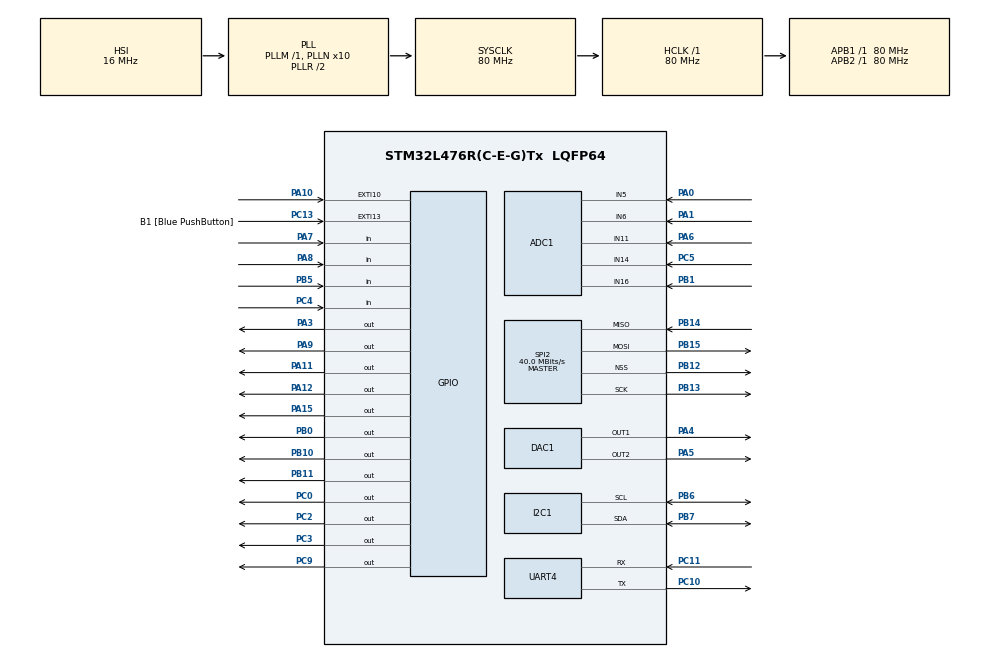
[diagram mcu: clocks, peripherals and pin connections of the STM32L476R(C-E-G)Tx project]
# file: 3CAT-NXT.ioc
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ADC1.Channel-0\#ChannelRegularConversion=ADC_CHANNEL_5
ADC1.NbrOfConversionFlag=1
ADC1.OffsetNumber-0\#ChannelRegularConversion=ADC_OFFSET_NONE
ADC1.Rank-0\#ChannelRegularConversion=1
ADC1.SamplingTime-0\#ChannelRegularConversion=ADC_SAMPLETIME_2CYCLES_5
ADC1.master=1
DAC1.DAC_Channel-DAC_OUT2=DAC_CHANNEL_2
FREERTOS.Tasks01=defaultTask,0,128,StartDefaultTask,Default,NULL,Dynamic,NULL,NULL
FREERTOS.configTIMER_TASK_PRIORITY=5
FREERTOS.configTIMER_TASK_STACK_DEPTH=500
FREERTOS.configTOTAL_HEAP_SIZE=70000
FREERTOS.configUSE_NEWLIB_REENTRANT=1
FREERTOS.configUSE_TIMERS=1
I2C1.Timing=0x10909CEC
Mcu.Family=STM32L4
Mcu.Name=STM32L476R(C-E-G)Tx
Mcu.Package=LQFP64
NVIC.EXTI15_10_IRQn=true\:5\:0\:true\:false\:true\:true\:true\:true
NVIC.PriorityGroup=NVIC_PRIORITYGROUP_4
NVIC.SPI2_IRQn=true\:5\:0\:false\:false\:true\:true\:true\:true
NVIC.TIM1_TRG_COM_TIM17_IRQn=true\:5\:0\:false\:false\:true\:true\:true\:true
NVIC.TIM1_UP_TIM16_IRQn=true\:5\:0\:false\:false\:true\:false\:true\:true
NVIC.TIM2_IRQn=true\:15\:0\:false\:false\:true\:false\:false\:true
NVIC.TIM5_IRQn=true\:15\:0\:true\:false\:true\:true\:true\:true
NVIC.TIM6_DAC_IRQn=true\:5\:0\:false\:false\:true\:true\:true\:true
NVIC.TIM7_IRQn=true\:5\:0\:false\:false\:true\:true\:true\:true
NVIC.TimeBase=TIM2_IRQn
NVIC.TimeBaseIP=TIM2
PA0.Signal=ADCx_IN5
PA1.Signal=ADCx_IN6
PA10.Signal=GPXTI10
PA11.Signal=GPIO_Output
PA12.Signal=GPIO_Output
PA13\ (JTMS-SWDIO).GPIO_Label=TMS
PA13\ (JTMS-SWDIO).Mode=Serial_Wire
PA13\ (JTMS-SWDIO).Signal=SYS_JTMS-SWDIO
PA14\ (JTCK-SWCLK).GPIO_Label=TCK
PA14\ (JTCK-SWCLK).Mode=Serial_Wire
PA14\ (JTCK-SWCLK).Signal=SYS_JTCK-SWCLK
PA15\ (JTDI).Signal=GPIO_Output
PA3.Signal=GPIO_Output
PA4.Signal=COMP_DAC11_group
PA5.Signal=COMP_DAC12_group
PA6.Signal=ADCx_IN11
PA7.Signal=GPIO_Input
PA8.Signal=GPIO_Input
PA9.Signal=GPIO_Output
PB0.Signal=GPIO_Output
PB1.Signal=ADCx_IN16
PB10.Signal=GPIO_Output
PB11.Signal=GPIO_Output
PB12.Mode=NSS_Signal_Hard_Output
PB12.Signal=SPI2_NSS
PB13.Mode=Full_Duplex_Master
PB13.Signal=SPI2_SCK
PB14.Mode=Full_Duplex_Master
PB14.Signal=SPI2_MISO
PB15.Mode=Full_Duplex_Master
PB15.Signal=SPI2_MOSI
PB5.Signal=GPIO_Input
PB6.Mode=I2C
PB6.Signal=I2C1_SCL
PB7.Mode=I2C
PB7.Signal=I2C1_SDA
PC0.Signal=GPIO_Output
PC10.Mode=Asynchronous
PC10.Signal=UART4_TX
PC11.Mode=Asynchronous
PC11.Signal=UART4_RX
PC13.GPIO_Label=B1 [Blue PushButton]
PC13.GPIO_ModeDefaultEXTI=GPIO_MODE_IT_FALLING
PC13.GPIO_PuPd=GPIO_NOPULL
PC13.Signal=GPXTI13
PC14-OSC32_IN\ (PC14).Mode=LSE-External-Oscillator
PC14-OSC32_IN\ (PC14).Signal=RCC_OSC32_IN
PC15-OSC32_OUT\ (PC15).Mode=LSE-External-Oscillator
PC15-OSC32_OUT\ (PC15).Signal=RCC_OSC32_OUT
PC2.Signal=GPIO_Output
PC3.Signal=GPIO_Output
PC4.Signal=GPIO_Input
PC5.Signal=ADCx_IN14
PC9.Signal=GPIO_Output
PH0-OSC_IN\ (PH0).Mode=HSE-External-Oscillator
PH0-OSC_IN\ (PH0).Signal=RCC_OSC_IN
PH1-OSC_OUT\ (PH1).Mode=HSE-External-Oscillator
PH1-OSC_OUT\ (PH1).Signal=RCC_OSC_OUT
ProjectManager.HeapSize=0x200
ProjectManager.StackSize=0x400
ProjectManager.TargetToolchain=STM32CubeIDE
RCC.ADCFreq_Value=64000000
RCC.AHBFreq_Value=80000000
RCC.APB1Freq_Value=80000000
RCC.APB1TimFreq_Value=80000000
RCC.APB2Freq_Value=80000000
RCC.APB2TimFreq_Value=80000000
RCC.CortexFreq_Value=80000000
RCC.FLatency-AdvancedSettings=FLASH_LATENCY_0
RCC.HCLKFreq_Value=80000000
RCC.HSE_VALUE=8000000
RCC.HSI_VALUE=16000000
RCC.MSIClockRange=RCC_MSIRANGE_5
RCC.MSI_VALUE=2000000
RCC.PLLN=10
RCC.PLLSourceVirtual=RCC_PLLSOURCE_HSI
RCC.SYSCLKFreq_VALUE=80000000
RCC.SYSCLKSource=RCC_SYSCLKSOURCE_PLLCLK
RCC.USBFreq_Value=64000000
RCC.VCOOutputFreq_Value=160000000
SH.ADCx_IN11.0=ADC1_IN11,IN11-Single-Ended
SH.ADCx_IN14.0=ADC1_IN14,IN14-Single-Ended
SH.ADCx_IN16.0=ADC1_IN16,IN16-Single-Ended
SH.ADCx_IN5.0=ADC1_IN5,IN5-Single-Ended
SH.ADCx_IN6.0=ADC1_IN6,IN6-Single-Ended
SH.COMP_DAC11_group.0=DAC1_OUT1,DAC_OUT1
SH.COMP_DAC12_group.0=DAC1_OUT2,DAC_OUT2
SPI2.BaudRatePrescaler=SPI_BAUDRATEPRESCALER_2
SPI2.CalculateBaudRate=40.0 MBits/s
SPI2.Direction=SPI_DIRECTION_2LINES
SPI2.Mode=SPI_MODE_MASTER
SPI2.VirtualNSS=VM_NSSHARD
SPI2.VirtualType=VM_MASTER
TIM16.Period=10000 - 1
TIM16.Prescaler=8000 - 1
TIM17.Period=50000-1
TIM17.Prescaler=48000-1
TIM5.AutoReloadPreload=TIM_AUTORELOAD_PRELOAD_ENABLE
TIM5.CounterMode=TIM_COUNTERMODE_DOWN
TIM5.Period=8000-1
TIM7.Period=1000-1
TIM7.Prescaler=20000-1
VP_FREERTOS_VS_CMSIS_V1.Mode=CMSIS_V1
VP_RTC_VS_RTC_Activate.Mode=RTC_Enabled
VP_RTC_VS_RTC_Calendar.Mode=RTC_Calendar
VP_SYS_VS_tim2.Mode=TIM2
VP_TIM16_VS_ClockSourceINT.Mode=Enable_Timer
VP_TIM17_VS_ClockSourceINT.Mode=Enable_Timer
VP_TIM5_VS_ClockSourceINT.Mode=Internal
VP_TIM7_VS_ClockSourceINT.Mode=Enable_Timer
board=NUCLEO-L476RG

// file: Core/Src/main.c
/* USER CODE BEGIN Header */
/**
  ******************************************************************************
  * @file           : main.c
  * @brief          : Main program body
  ******************************************************************************
  * @attention
  *
  * <h2><center>&copy; Copyright (c) 2022 STMicroelectronics.
  * All rights reserved.</center></h2>
  *
  * This software component is licensed by ST under BSD 3-Clause license,
  * the "License"; You may not use this file except in compliance with the
  * License. You may obtain a copy of the License at:
  *                        opensource.org/licenses/BSD-3-Clause
  *
  ******************************************************************************
  */
/* USER CODE END Header */
#include "main.h"
#include "cmsis_os.h"

ADC_HandleTypeDef hadc1;

DAC_HandleTypeDef hdac1;

I2C_HandleTypeDef hi2c1;

RTC_HandleTypeDef hrtc;

SPI_HandleTypeDef hspi2;

TIM_HandleTypeDef htim5;
TIM_HandleTypeDef htim7;
TIM_HandleTypeDef htim16;
TIM_HandleTypeDef htim17;

UART_HandleTypeDef huart4;
/* USER CODE BEGIN PV */
uint8_t timer_counter = 0;		//TEST
uint8_t beacon_counter = 0;		//COMMS BEACON
uint8_t timeout_counter = 0; 	//COMMS TIMEOUT
uint8_t start_timer = false;	//TO SKIP STARTING TIMER IRQ
uint8_t stop_timer = false;		//TO SKIP STOPPING TIMER IRQ

uint8_t photo_vect[]={0xFF, 0xD8, 0xFF, 0xE0, 0x00, 0x10, 0x4A, 0x46, 0x49, 0x46, 0x00, 0x01, 0x01, 0x00, 0x00, 0x01,
	  				0x00, 0x01, 0x00, 0x00, 0xFF, 0xE2, 0x02, 0x28, 0x49, 0x43, 0x43, 0x5F, 0x50, 0x52, 0x4F, 0x46,
	  				0x49, 0x4C, 0x45, 0x00, 0x01, 0x01, 0x00, 0x00, 0x02, 0x18, 0x00, 0x00, 0x00, 0x00, 0x04, 0x30,
	  				0x00, 0x00, 0x6D, 0x6E, 0x74, 0x72, 0x52, 0x47, 0x42, 0x20, 0x58, 0x59, 0x5A, 0x20, 0x00, 0x00,
	  				0x00, 0x00, 0x00, 0x00, 0x00, 0x00, 0x00, 0x00, 0x00, 0x00, 0x61, 0x63, 0x73, 0x70, 0x00, 0x00,
	  				0x00, 0x00, 0x00, 0x00, 0x00, 0x00, 0x00, 0x00, 0x00, 0x00, 0x00, 0x00, 0x00, 0x00, 0x00, 0x00,
	  				0x00, 0x00, 0x00, 0x00, 0x00, 0x00, 0x00, 0x00, 0x00, 0x01, 0x00, 0x00, 0xF6, 0xD6, 0x00, 0x01,
	  				0x00, 0x00, 0x00, 0x00, 0xD3, 0x2D, 0x00, 0x00, 0x00, 0x00, 0x00, 0x00, 0x00, 0x00, 0x00, 0x00,
	  				0x00, 0x00, 0x00, 0x00, 0x00, 0x00, 0x00, 0x00, 0x00, 0x00, 0x00, 0x00, 0x00, 0x00, 0x00, 0x00,
	  				0x00, 0x00, 0x00, 0x00, 0x00, 0x00, 0x00, 0x00, 0x00, 0x00, 0x00, 0x00, 0x00, 0x00, 0x00, 0x00,
	  				0x00, 0x00, 0x00, 0x00, 0x00, 0x00, 0x00, 0x00, 0x00, 0x09, 0x64, 0x65, 0x73, 0x63, 0x00, 0x00,
	  				0x00, 0xF0, 0x00, 0x00, 0x00, 0x74, 0x72, 0x58, 0x59, 0x5A, 0x00, 0x00, 0x01, 0x64, 0x00, 0x00,
	  				0x00, 0x14, 0x67, 0x58, 0x59, 0x5A, 0x00, 0x00, 0x01, 0x78, 0x00, 0x00, 0x00, 0x14, 0x62, 0x58,
	  				0x59, 0x5A, 0x00, 0x00, 0x01, 0x8C, 0x00, 0x00, 0x00, 0x14, 0x72, 0x54, 0x52, 0x43, 0x00, 0x00,
	  				0x01, 0xA0, 0x00, 0x00, 0x00, 0x28, 0x67, 0x54, 0x52, 0x43, 0x00, 0x00, 0x01, 0xA0, 0x00, 0x00,
	  				0x00, 0x28, 0x62, 0x54, 0x52, 0x43, 0x00, 0x00, 0x01, 0xA0, 0x00, 0x00, 0x00, 0x28, 0x77, 0x74,
	  				0x70, 0x74, 0x00, 0x00, 0x01, 0xC8, 0x00, 0x00, 0x00, 0x14, 0x63, 0x70, 0x72, 0x74, 0x00, 0x00,
	  				0x01, 0xDC, 0x00, 0x00, 0x00, 0x3C, 0x6D, 0x6C, 0x75, 0x63, 0x00, 0x00, 0x00, 0x00, 0x00, 0x00,
	  				0x00, 0x01, 0x00, 0x00, 0x00, 0x0C, 0x65, 0x6E, 0x55, 0x53, 0x00, 0x00, 0x00, 0x58, 0x00, 0x00,
	  				0x00, 0x1C, 0x00, 0x73, 0x00, 0x52, 0x00, 0x47, 0x00, 0x42, 0x00, 0x00, 0x00, 0x00, 0x00, 0x00,
	  				0x00, 0x00, 0x00, 0x00, 0x00, 0x00, 0x00, 0x00, 0x00, 0x00, 0x00, 0x00, 0x00, 0x00, 0x00, 0x00,
	  				0x00, 0x00, 0x00, 0x00, 0x00, 0x00, 0x00, 0x00, 0x00, 0x00, 0x00, 0x00, 0x00, 0x00, 0x00, 0x00,
	  				0x00, 0x00, 0x00, 0x00, 0x00, 0x00, 0x00, 0x00, 0x00, 0x00, 0x00, 0x00, 0x00, 0x00, 0x00, 0x00,
	  				0x00, 0x00, 0x00, 0x00, 0x00, 0x00, 0x00, 0x00, 0x00, 0x00, 0x00, 0x00, 0x00, 0x00, 0x00, 0x00,
	  				0x00, 0x00, 0x00, 0x00, 0x00, 0x00, 0x00, 0x00, 0x00, 0x00, 0x58, 0x59, 0x5A, 0x20, 0x00, 0x00,
	  				0x00, 0x00, 0x00, 0x00, 0x6F, 0xA2, 0x00, 0x00, 0x38, 0xF5, 0x00, 0x00, 0x03, 0x90, 0x58, 0x59,
	  				0x5A, 0x20, 0x00, 0x00, 0x00, 0x00, 0x00, 0x00, 0x62, 0x99, 0x00, 0x00, 0xB7, 0x85, 0x00, 0x00,
	  				0x18, 0xDA, 0x58, 0x59, 0x5A, 0x20, 0x00, 0x00, 0x00, 0x00, 0x00, 0x00, 0x24, 0xA0, 0x00, 0x00,
	  				0x0F, 0x84, 0x00, 0x00, 0xB6, 0xCF, 0x70, 0x61, 0x72, 0x61, 0x00, 0x00, 0x00, 0x00, 0x00, 0x04,
	  				0x00, 0x00, 0x00, 0x02, 0x66, 0x66, 0x00, 0x00, 0xF2, 0xA7, 0x00, 0x00, 0x0D, 0x59, 0x00, 0x00,
	  				0x13, 0xD0, 0x00, 0x00, 0x0A, 0x5B, 0x00, 0x00, 0x00, 0x00, 0x00, 0x00, 0x00, 0x00, 0x58, 0x59,
	  				0x5A, 0x20, 0x00, 0x00, 0x00, 0x00, 0x00, 0x00, 0xF6, 0xD6, 0x00, 0x01, 0x00, 0x00, 0x00, 0x00,
	  				0xD3, 0x2D, 0x6D, 0x6C, 0x75, 0x63, 0x00, 0x00, 0x00, 0x00, 0x00, 0x00, 0x00, 0x01, 0x00, 0x00,
	  				0x00, 0x0C, 0x65, 0x6E, 0x55, 0x53, 0x00, 0x00, 0x00, 0x20, 0x00, 0x00, 0x00, 0x1C, 0x00, 0x47,
	  				0x00, 0x6F, 0x00, 0x6F, 0x00, 0x67, 0x00, 0x6C, 0x00, 0x65, 0x00, 0x20, 0x00, 0x49, 0x00, 0x6E,
	  				0x00, 0x63, 0x00, 0x2E, 0x00, 0x20, 0x00, 0x32, 0x00, 0x30, 0x00, 0x31, 0x00, 0x36, 0xFF, 0xDB,
	  				0x00, 0x43, 0x00, 0x03, 0x02, 0x02, 0x02, 0x02, 0x02, 0x03, 0x02, 0x02, 0x02, 0x03, 0x03, 0x03,
	  				0x03, 0x04, 0x06, 0x04, 0x04, 0x04, 0x04, 0x04, 0x08, 0x06, 0x06, 0x05, 0x06, 0x09, 0x08, 0x0A,
	  				0x0A, 0x09, 0x08, 0x09, 0x09, 0x0A, 0x0C, 0x0F, 0x0C, 0x0A, 0x0B, 0x0E, 0x0B, 0x09, 0x09, 0x0D,
	  				0x11, 0x0D, 0x0E, 0x0F, 0x10, 0x10, 0x11, 0x10, 0x0A, 0x0C, 0x12, 0x13, 0x12, 0x10, 0x13, 0x0F,
	  				0x10, 0x10, 0x10, 0xFF, 0xDB, 0x00, 0x43, 0x01, 0x03, 0x03, 0x03, 0x04, 0x03, 0x04, 0x08, 0x04,
	  				0x04, 0x08, 0x10, 0x0B, 0x09, 0x0B, 0x10, 0x10, 0x10, 0x10, 0x10, 0x10, 0x10, 0x10, 0x10, 0x10,
	  				0x10, 0x10, 0x10, 0x10, 0x10, 0x10, 0x10, 0x10, 0x10, 0x10, 0x10, 0x10, 0x10, 0x10, 0x10, 0x10,
	  				0x10, 0x10, 0x10, 0x10, 0x10, 0x10, 0x10, 0x10, 0x10, 0x10, 0x10, 0x10, 0x10, 0x10, 0x10, 0x10,
	  				0x10, 0x10, 0x10, 0x10, 0x10, 0x10, 0x10, 0x10, 0xFF, 0xC0, 0x00, 0x11, 0x08, 0x00, 0x78, 0x00,
	  				0xA0, 0x03, 0x01, 0x22, 0x00, 0x02, 0x11, 0x01, 0x03, 0x11, 0x01, 0xFF, 0xC4, 0x00, 0x1C, 0x00,
	  				0x00, 0x01, 0x05, 0x01, 0x01, 0x01, 0x00, 0x00, 0x00, 0x00, 0x00, 0x00, 0x00, 0x00, 0x00, 0x00,
	  				0x04, 0x00, 0x05, 0x06, 0x07, 0x08, 0x09, 0x01, 0x0A, 0xFF, 0xC4, 0x00, 0x35, 0x10, 0x00, 0x02,
	  				0x01, 0x03, 0x02, 0x04, 0x04, 0x05, 0x03, 0x02, 0x07, 0x01, 0x00, 0x00, 0x00, 0x00, 0x00, 0x04,
	  				0x05, 0x06, 0x07, 0x14, 0x01, 0x24, 0x08, 0x15, 0x34, 0x61, 0x11, 0x16, 0x44, 0x54, 0x02, 0x17,
	  				0x25, 0x31, 0x64, 0x21, 0x35, 0x51, 0x26, 0x41, 0x27, 0x33, 0x36, 0x45, 0x65, 0x81, 0x84, 0xF0,
	  				0xFF, 0xC4, 0x00, 0x19, 0x01, 0x00, 0x03, 0x01, 0x01, 0x01, 0x00, 0x00, 0x00, 0x00, 0x00, 0x00,
	  				0x00, 0x00, 0x00, 0x00, 0x00, 0x00, 0x03, 0x04, 0x05, 0x01, 0x06, 0xFF, 0xC4, 0x00, 0x2A, 0x11,
	  				0x01, 0x00, 0x02, 0x00, 0x05, 0x03, 0x03, 0x02, 0x07, 0x00, 0x00, 0x00, 0x00, 0x00, 0x00, 0x00,
	  				0x00, 0x03, 0x13, 0x01, 0x04, 0x11, 0x41, 0x61, 0x05, 0x14, 0x23, 0x02, 0x12, 0x51, 0x21, 0x31,
	  				0x24, 0x33, 0x52, 0x62, 0x91, 0xA1, 0xE1, 0xFF, 0xDA, 0x00, 0x0C, 0x03, 0x01, 0x00, 0x02, 0x11,
	  				0x03, 0x11, 0x00, 0x3F, 0x00, 0xEA, 0x58, 0x84, 0x20, 0x08, 0xF5, 0x6B, 0x52, 0xA1, 0x48, 0x53,
	  				0xED, 0x4E, 0xB9, 0xF6, 0x4C, 0xE4, 0xAF, 0x10, 0x97, 0x53, 0xCF, 0x95, 0x43, 0x73, 0x8E, 0xBD,
	  				0xB4, 0xF4, 0x66, 0x95, 0xE3, 0x46, 0xFC, 0x66, 0x35, 0xE4, 0x78, 0x57, 0xB6, 0xA7, 0x3F, 0xEA,
	  				0xC7, 0x1E, 0x98, 0x6B, 0xF1, 0x0C, 0xEA, 0xBB, 0xA9, 0xAD, 0xD7, 0x41, 0x36, 0x35, 0x22, 0xB2,
	  				0xCE, 0x73, 0x86, 0x8F, 0x25, 0xB6, 0x71, 0x78, 0x23, 0xB2, 0x89, 0xA2, 0x08, 0xDE, 0xF2, 0x50,
	  				0xD1, 0x48, 0x8A, 0xE1, 0x8D, 0x2D, 0x92, 0xB9, 0x67, 0x08, 0xA3, 0x7B, 0xC1, 0x55, 0x72, 0x05,
	  				0xA8, 0x9E, 0x61, 0x2B, 0xF4, 0xC4, 0x7E, 0x24, 0x95, 0x09, 0x08, 0xAC, 0xB0, 0x22, 0x89, 0xF7,
	  				0x1D, 0x65, 0xBA, 0xB0, 0xB5, 0x13, 0xDA, 0x8A, 0xAB, 0x90, 0x6A, 0xE4, 0xFD, 0xC5, 0xE5, 0xBF,
	  				0xFE, 0xF1, 0x24, 0x02, 0x6C, 0x68, 0x47, 0xF9, 0x3F, 0x71, 0x61, 0x8E, 0xAD, 0x82, 0x0A, 0xAB,
	  				0x90, 0x6A, 0x04, 0x1D, 0x9B, 0x10, 0xD0, 0x10, 0x13, 0x0C, 0x76, 0x0A, 0xC3, 0x00, 0xFA, 0x36,
	  				0x28, 0x8E, 0x29, 0x2F, 0x54, 0x7D, 0xAA, 0xA3, 0x1A, 0xD3, 0x47, 0x7C, 0x1A, 0x6F, 0x4F, 0x0D,
	  				0x3B, 0x68, 0x5A, 0xB5, 0xB5, 0x5C, 0x85, 0x1D, 0x00, 0xCC, 0xDB, 0x9F, 0x6D, 0x3E, 0xC7, 0x28,
	  				0x6F, 0xCD, 0xC8, 0x7A, 0xF0, 0x56, 0x4D, 0xBC, 0xEB, 0xDB, 0x4F, 0x46, 0x12, 0xF9, 0x66, 0xAB,
	  				0xEC, 0xAD, 0x54, 0xD5, 0x95, 0x24, 0xE5, 0x61, 0x28, 0xDB, 0xCE, 0xFA, 0xD2, 0x2A, 0xDA, 0x6F,
	  				0x12, 0xA6, 0xDC, 0x46, 0x1C, 0x8A, 0xB7, 0x52, 0x66, 0x35, 0x82, 0x91, 0x5A, 0x41, 0x4A, 0x27,
	  				0xB5, 0x1A, 0xA5, 0xB6, 0x64, 0x83, 0xFD, 0xAF, 0x7A, 0x42, 0xA5, 0x9C, 0x00, 0x8F, 0xCB, 0x38,
	  				0x08, 0xA2, 0x79, 0x81, 0x7D, 0x61, 0x20, 0x89, 0x87, 0xEC, 0x00, 0x52, 0x90, 0xE1, 0x6A, 0x27,
	  				0x86, 0x3A, 0xE1, 0xE1, 0xAA, 0x35, 0x7A, 0x92, 0x40, 0x6A, 0x6D, 0x3E, 0xE1, 0x41, 0x6D, 0xA7,
	  				0xDC, 0x6A, 0xC3, 0x00, 0x29, 0x44, 0xFB, 0x82, 0xB6, 0x3A, 0x82, 0x00, 0x35, 0x02, 0x0E, 0xCD,
	  				0x82, 0x61, 0x80, 0x34, 0xB9, 0xD5, 0x1E, 0xA8, 0x9F, 0x71, 0xD7, 0x0C, 0x40, 0x02, 0x05, 0xA8,
	  				0x21, 0x12, 0x87, 0x4D, 0x78, 0xC6, 0xBE, 0xFA, 0x4B, 0xCA, 0x79, 0x1A, 0x15, 0xED, 0xA7, 0xAC,
	  				0x31, 0xFB, 0x6E, 0x76, 0x0B, 0x96, 0x98, 0xE7, 0x12, 0x8D, 0xBC, 0xEE, 0xED, 0xB7, 0x48, 0xA5,
	  				0x42, 0xE1, 0x7C, 0x31, 0x55, 0xBA, 0xB4, 0x56, 0xA1, 0x70, 0x12, 0x93, 0x87, 0xCC, 0x6B, 0x38,
	  				0x12, 0x59, 0xCD, 0xD1, 0x2B, 0x89, 0xFA, 0x3C, 0x0F, 0xE5, 0x9A, 0x18, 0x24, 0x09, 0x50, 0xB9,
	  				0x87, 0xB1, 0x21, 0x4D, 0xEF, 0x09, 0x07, 0x96, 0xE7, 0x26, 0x1A, 0xE8, 0x49, 0x04, 0x4D, 0x1F,
	  				0x87, 0xD6, 0x8A, 0xB7, 0x80, 0x8A, 0x53, 0xD4, 0xD9, 0x36, 0x51, 0x34, 0x61, 0xC2, 0x9B, 0x71,
	  				0x14, 0xD5, 0x22, 0xAD, 0xCC, 0x66, 0x34, 0x28, 0x0A, 0x96, 0x70, 0x8F, 0xC4, 0xF5, 0x63, 0xB6,
	  				0x1E, 0xD4, 0x4A, 0x27, 0xBA, 0x00, 0x75, 0x6D, 0x3D, 0xA9, 0x1F, 0x6D, 0x3E, 0xE4, 0xAF, 0x0F,
	  				0x6A, 0x34, 0xCB, 0x26, 0x48, 0x0D, 0x42, 0x10, 0x80, 0x04, 0x05, 0x1D, 0x41, 0x00, 0x05, 0x10,
	  				0x50, 0x29, 0x28, 0x26, 0xC4, 0xA2, 0x7D, 0xC2, 0x84, 0xA0, 0x04, 0xD9, 0x49, 0x8C, 0x36, 0x82,
	  				0xA5, 0xB7, 0x8A, 0x93, 0x69, 0x6E, 0x15, 0xEF, 0x14, 0x3C, 0x5E, 0x74, 0xD5, 0x2A, 0xE2, 0x85,
	  				0x53, 0xBE, 0x87, 0x6B, 0x05, 0xD2, 0xFB, 0xE3, 0xF9, 0x06, 0xAC, 0x3C, 0xC9, 0x42, 0x6B, 0x86,
	  				0xF2, 0x6A, 0xEC, 0x86, 0xAA, 0x79, 0x3F, 0xAA, 0x12, 0x09, 0x69, 0x8C, 0x3D, 0x8A, 0x43, 0x81,
	  				0x66, 0x61, 0x8D, 0x4D, 0xCC, 0x02, 0x36, 0xE7, 0x61, 0xAA, 0x59, 0xC4, 0x7F, 0x80, 0x01, 0x1B,
	  				0x73, 0xB0, 0xA2, 0x46, 0xA6, 0xDC, 0xCC, 0x25, 0x54, 0x9C, 0x3B, 0xD3, 0x0D, 0x28, 0x8A, 0x48,
	  				0xE5, 0xB6, 0xE8, 0x03, 0xB4, 0x4C, 0x3B, 0xD3, 0x0D, 0x28, 0x8C, 0x2A, 0x39, 0x6D, 0xBA, 0x69,
	  				0xFA, 0x7B, 0x83, 0xF8, 0x3A, 0x3E, 0xDC, 0xB7, 0x5C, 0x5C, 0xE7, 0xB1, 0x1B, 0xC3, 0x2E, 0x1E,
	  				0x1E, 0xEC, 0x9D, 0x2B, 0x64, 0xE9, 0x7F, 0x35, 0x56, 0x88, 0xE5, 0xD4, 0x0E, 0xFA, 0x42, 0xCA,
	  				0xAB, 0x39, 0x1C, 0xC4, 0x0F, 0x3C, 0xB8, 0x3B, 0x45, 0x3D, 0xA1, 0x9F, 0x34, 0xB6, 0xEC, 0x1C,
	  				0xBF, 0x6F, 0x05, 0x3C, 0xBC, 0x2E, 0x90, 0x8F, 0xB6, 0x5C, 0x17, 0xBA, 0xA4, 0xB7, 0x33, 0x15,
	  				0x47, 0xF8, 0x7C, 0x8E, 0x22, 0x85, 0x54, 0xD8, 0x5B, 0xC0, 0x47, 0xC4, 0x16, 0xD8, 0x20, 0x5B,
	  				0xC0, 0x21, 0x08, 0x42, 0x80, 0x46, 0xC1, 0x4F, 0x1C, 0xEA, 0x8F, 0x40, 0xDB, 0x78, 0x3A, 0x89,
	  				0x40, 0x40, 0xB5, 0x04, 0x5D, 0xC1, 0x4E, 0xFA, 0x4B, 0x28, 0x8C, 0xBA, 0xB8, 0x4F, 0x25, 0x95,
	  				0xA7, 0x72, 0x9D, 0xBA, 0xFC, 0x21, 0xD9, 0xDB, 0xAB, 0x07, 0xAA, 0x0F, 0xC2, 0x68, 0x93, 0x5A,
	  				0xFD, 0x9A, 0x57, 0xF4, 0xD4, 0xB0, 0xA7, 0xEB, 0xA8, 0x3A, 0x65, 0x46, 0x9D, 0x9A, 0x7D, 0x45,
	  				0x3C, 0x3F, 0x9D, 0x4C, 0xD5, 0x78, 0xB8, 0xFB, 0xA5, 0x69, 0xA5, 0x5A, 0x46, 0x8A, 0x4B, 0x2D,
	  				0xAF, 0x75, 0xFD, 0x87, 0x43, 0x9D, 0x8A, 0x63, 0xAA, 0xCC, 0x7C, 0xB1, 0xAD, 0xF8, 0xB1, 0x1F,
	  				0x22, 0x2B, 0x1E, 0x46, 0x94, 0xE7, 0x36, 0x2A, 0xA6, 0xD3, 0xC3, 0x68, 0x2E, 0xE6, 0xDE, 0x09,
	  				0xCA, 0xC2, 0x79, 0xB9, 0xC9, 0xAE, 0xAD, 0xD2, 0x12, 0xDD, 0x78, 0xF7, 0xAD, 0x2B, 0xC9, 0xB9,
	  				0x34, 0x55, 0x6E, 0x76, 0x6D, 0xCE, 0xC0, 0x8D, 0xA7, 0xDC, 0x2D, 0x4D, 0xE2, 0xB9, 0xC9, 0x02,
	  				0x61, 0xE6, 0x74, 0x45, 0x65, 0x14, 0x4D, 0x36, 0xF4, 0xC4, 0xA2, 0x88, 0xC2, 0xEE, 0xDB, 0x74,
	  				0xE8, 0x07, 0x0C, 0xBC, 0x3D, 0xC1, 0xDB, 0x78, 0x15, 0x2B, 0x8A, 0xD3, 0xFD, 0x41, 0xE8, 0xD4,
	  				0x22, 0xBC, 0x2D, 0x59, 0xF8, 0x3B, 0x56, 0xAA, 0x97, 0x1A, 0xE0, 0xA3, 0x97, 0x2A, 0xEF, 0x46,
	  				0xA1, 0xAA, 0xAA, 0xC9, 0x8A, 0x56, 0x1E, 0x2F, 0xE6, 0x35, 0x68, 0x8E, 0x22, 0x89, 0x6F, 0x53,
	  				0x50, 0xCF, 0x9A, 0x5B, 0x76, 0x36, 0xAE, 0x42, 0x37, 0x31, 0x07, 0x47, 0xC5, 0xB7, 0x75, 0x2E,
	  				0x0B, 0xC9, 0xEC, 0xBA, 0x35, 0x0C, 0x15, 0xC4, 0x27, 0x10, 0x93, 0x97, 0x52, 0x7B, 0x65, 0x98,
	  				0xA4, 0x52, 0x43, 0x55, 0xEE, 0xBF, 0x13, 0x97, 0x52, 0x79, 0xB7, 0xB7, 0x8A, 0x44, 0xFA, 0x35,
	  				0x07, 0x5B, 0x0D, 0x67, 0xE9, 0x5B, 0xA8, 0xAB, 0x79, 0xAF, 0x7D, 0x57, 0xDA, 0x0A, 0x76, 0xAE,
	  				0x54, 0xFA, 0x86, 0x80, 0xB7, 0xBC, 0x3D, 0xBD, 0x58, 0x5A, 0xF9, 0x59, 0xC7, 0x51, 0xC4, 0xFC,
	  				0xB0, 0xB5, 0x38, 0x33, 0x9C, 0x4E, 0xA8, 0xDE, 0xBD, 0x89, 0x4F, 0xA5, 0xEA, 0xCB, 0x56, 0xA1,
	  				0xE2, 0x72, 0xDC, 0xD3, 0x76, 0xE5, 0xBB, 0x3A, 0x96, 0xEF, 0x09, 0x3C, 0x2C, 0xB2, 0x79, 0x65,
	  				0xB7, 0x6D, 0x0D, 0xF6, 0xC9, 0xFA, 0x58, 0x7D, 0x4A, 0x6F, 0x9C, 0x4F, 0x60, 0xA4, 0x2A, 0xB2,
	  				0x83, 0x9C, 0xA6, 0xFA, 0xD2, 0xC0, 0xB6, 0x49, 0xE6, 0x4A, 0x67, 0x16, 0x5C, 0xB4, 0x3F, 0x38,
	  				0xEB, 0x4B, 0x21, 0x8E, 0xDD, 0xF4, 0x64, 0xCD, 0x9B, 0xAB, 0x66, 0x54, 0x04, 0x2F, 0x6A, 0xB2,
	  				0xCF, 0xE6, 0x6F, 0xA1, 0x4A, 0x7E, 0x5A, 0x1D, 0xE8, 0x76, 0xB0, 0x5D, 0x16, 0x6C, 0x32, 0xDD,
	  				0xB6, 0x88, 0xF8, 0x9B, 0x0A, 0x6C, 0x14, 0x84, 0xE2, 0x0A, 0x50, 0x14, 0x28, 0x03, 0x4B, 0x5C,
	  				0x2B, 0xC1, 0x55, 0x57, 0x8D, 0x6F, 0x5E, 0x29, 0xF6, 0xD3, 0x79, 0xC2, 0x54, 0xA4, 0x3B, 0xCE,
	  				0x16, 0x05, 0x27, 0x41, 0xE6, 0x35, 0xBD, 0x15, 0xDC, 0x47, 0xF2, 0xDC, 0x86, 0x1B, 0xB7, 0xD1,
	  				0x5F, 0xD3, 0xD6, 0x7F, 0x9C, 0x2B, 0xD0, 0x95, 0xAD, 0xE3, 0xA3, 0xD1, 0xA6, 0xDA, 0x37, 0xAC,
	  				0x4D, 0x1E, 0x8A, 0x71, 0x7D, 0x09, 0x8F, 0xF8, 0xB0, 0x4F, 0x0E, 0x79, 0x44, 0x45, 0x41, 0x9D,
	  				0x92, 0x5C, 0xDF, 0xC1, 0xB9, 0xCC, 0x9C, 0x7D, 0xA2, 0x94, 0xA4, 0xE6, 0x30, 0xDA, 0xC1, 0x2C,
	  				0x0A, 0x7A, 0x61, 0x18, 0x79, 0xE8, 0x99, 0xCE, 0xAD, 0x44, 0x9C, 0x2B, 0x5C, 0x31, 0xD6, 0x26,
	  				0x63, 0x0F, 0x62, 0xE9, 0xE9, 0xEA, 0xE5, 0xE7, 0x9D, 0x35, 0xA4, 0xEB, 0x04, 0x5C, 0x81, 0x52,
	  				0xEA, 0x54, 0xFF, 0x00, 0xB5, 0x24, 0x9E, 0xCD, 0x43, 0x2F, 0xF1, 0x09, 0xC4, 0xE4, 0xE5, 0xD4,
	  				0x94, 0x6D, 0x14, 0x9E, 0xFE, 0x9F, 0xF6, 0x85, 0x3F, 0xF3, 0x22, 0xAA, 0xF2, 0xBF, 0x95, 0x79,
	  				0xE7, 0xD2, 0xBD, 0xA1, 0x20, 0xB4, 0xF6, 0xAE, 0x72, 0xE4, 0x35, 0xFF, 0x00, 0x14, 0x97, 0x58,
	  				0xD9, 0x01, 0xD2, 0xC9, 0x6E, 0xC8, 0xAE, 0x61, 0xAA, 0xAD, 0x3D, 0x37, 0xF2, 0x4E, 0x83, 0xF9,
	  				0xA9, 0x9D, 0xF5, 0x5F, 0x68, 0x0B, 0x6F, 0x6C, 0x9D, 0x2B, 0x0F, 0x3C, 0xDD, 0x71, 0x53, 0xA3,
	  				0xFD, 0x3F, 0x0C, 0x55, 0x37, 0xE6, 0xF0, 0x79, 0xF2, 0x7B, 0x06, 0x98, 0xCC, 0x4E, 0x9F, 0x4B,
	  				0xA3, 0x03, 0x61, 0xF1, 0x2F, 0x68, 0x9E, 0x39, 0x39, 0xC5, 0x2F, 0x2B, 0x07, 0x5A, 0x41, 0xF5,
	  				0xBE, 0xD0, 0xCF, 0xF1, 0x34, 0xDB, 0xD5, 0x23, 0x5B, 0x24, 0x46, 0x9B, 0x7B, 0x41, 0xBD, 0x52,
	  				0x4A, 0x7E, 0x21, 0xAD, 0xA8, 0x8A, 0x6D, 0x14, 0xF1, 0x11, 0x49, 0x12, 0x29, 0xBC, 0x3C, 0xB9,
	  				0x17, 0x96, 0x5A, 0xBE, 0xC8, 0xA5, 0x27, 0x6D, 0xFC, 0xB7, 0x03, 0xF9, 0x64, 0x52, 0xA1, 0xAF,
	  				0x11, 0xA6, 0xDA, 0xC1, 0x2F, 0x6A, 0xDE, 0x9B, 0x9C, 0x4E, 0x2D, 0xBC, 0x23, 0x2F, 0xCB, 0x51,
	  				0xF3, 0x8E, 0x35, 0x9D, 0x83, 0xBB, 0x1D, 0x0C, 0xD6, 0xEC, 0xEF, 0x6B, 0xDA, 0xEF, 0xA8, 0xA8,
	  				0x9B, 0x90, 0xF4, 0xC4, 0xA6, 0x0E, 0x0E, 0xD0, 0xB2, 0xE5, 0xAD, 0x5A, 0x35, 0x24, 0x5E, 0xF5,
	  				0x12, 0xB4, 0xB6, 0x54, 0x7B, 0xCE, 0x55, 0x0A, 0x1A, 0xAD, 0xB4, 0xF9, 0x3C, 0x59, 0x65, 0xBC,
	  				0x25, 0xEC, 0xE4, 0x62, 0xAA, 0xDE, 0xD5, 0xBD, 0x4D, 0xB5, 0xEE, 0xD5, 0x2B, 0xFE, 0x4F, 0xDC,
	  				0xD9, 0x52, 0xD0, 0xFC, 0xE1, 0xA6, 0xF3, 0x4A, 0xAA, 0xAC, 0xB6, 0xF9, 0x8D, 0x67, 0x42, 0xA2,
	  				0xE6, 0x21, 0x98, 0xA9, 0x9F, 0xF0, 0xF7, 0x40, 0x8D, 0x96, 0x04, 0xB5, 0x37, 0x86, 0x35, 0x29,
	  				0x47, 0xBD, 0x30, 0xD6, 0x0A, 0x48, 0x82, 0x46, 0x8B, 0xA7, 0xA8, 0xF2, 0xE0, 0xA4, 0xE8, 0xFC,
	  				0x35, 0x47, 0x5A, 0x22, 0x8F, 0xCC, 0x54, 0xB5, 0x62, 0x69, 0xBC, 0x35, 0x8C, 0x49, 0xA5, 0xAB,
	  				0x6D, 0x5E, 0xE3, 0x28, 0x8A, 0xA9, 0x4D, 0xED, 0x7A, 0x13, 0x1A, 0x71, 0x61, 0x0F, 0x99, 0x54,
	  				0x1D, 0x00, 0x96, 0x4F, 0xD0, 0xC2, 0xF5, 0x66, 0x5F, 0xE2, 0x96, 0xDB, 0xF2, 0x75, 0x54, 0x79,
	  				0xDE, 0xAD, 0xD2, 0xBE, 0x9B, 0x15, 0xB2, 0xDB, 0xA9, 0x3D, 0x4A, 0x78, 0xE2, 0x86, 0xAD, 0x75,
	  				0x62, 0xA5, 0x28, 0xF1, 0x4B, 0x51, 0xC8, 0x96, 0xAF, 0x27, 0xEE, 0x09, 0xC9, 0xFB, 0x9E, 0xA1,
	  				0xE3, 0x71, 0x53, 0xEA, 0x26, 0xF2, 0x6D, 0x1D, 0x00, 0xB0, 0xC9, 0xC1, 0xD6, 0x14, 0x6C, 0x55,
	  				0x2B, 0x45, 0xED, 0x3D, 0xE1, 0x95, 0x5B, 0xA3, 0xF3, 0x02, 0xA9, 0x3A, 0xC2, 0xB8, 0xB5, 0x6D,
	  				0x67, 0x42, 0x84, 0xDE, 0x51, 0x0E, 0x15, 0x35, 0x05, 0xD8, 0xB9, 0x0F, 0x51, 0xED, 0x4A, 0xDB,
	  				0x94, 0xA0, 0xF2, 0xD4, 0xC3, 0x33, 0x55, 0x27, 0x61, 0xEA, 0xAA, 0x92, 0x53, 0xF1, 0x04, 0xDD,
	  				0xD4, 0x9C, 0xAC, 0x25, 0x33, 0xA6, 0x9E, 0xDD, 0x97, 0x05, 0xBD, 0xAF, 0x3D, 0x0B, 0xAF, 0x0A,
	  				0x86, 0x2A, 0xB7, 0x73, 0x38, 0x95, 0xD3, 0xD6, 0xAF, 0xCB, 0x71, 0x78, 0x29, 0x22, 0x58, 0x14,
	  				0x45, 0x36, 0xF7, 0x34, 0x50, 0x51, 0x35, 0x21, 0x65, 0x5B, 0xD7, 0x11, 0x73, 0xAD, 0x39, 0x9C,
	  				0x8B, 0x7D, 0x47, 0x4E, 0xF1, 0x2B, 0x5B, 0xC7, 0x5E, 0x79, 0x3D, 0xA5, 0x20, 0xF0, 0x7A, 0xD2,
	  				0x28, 0xA4, 0x3A, 0x3C, 0xAF, 0x65, 0xBB, 0x69, 0xD2, 0xE0, 0xAD, 0xED, 0x5B, 0xD3, 0x0D, 0x67,
	  				0x60, 0xE5, 0x82, 0xD2, 0x7C, 0x3D, 0xBD, 0x30, 0xAE, 0x77, 0x48, 0x2B, 0x05, 0x8C, 0xD3, 0x12,
	  				0x9B, 0xD4, 0x1D, 0x51, 0x9C, 0xE9, 0x6A, 0xB6, 0xE7, 0x38, 0xDF, 0x17, 0xB2, 0x9C, 0x3D, 0xD2,
	  				0xA9, 0xEF, 0xA6, 0xB7, 0x6D, 0x84, 0xD3, 0xF6, 0x59, 0x04, 0xDB, 0xE7, 0x55, 0x2E, 0xBA, 0x2B,
	  				0x16, 0x9E, 0x9E, 0x3A, 0x28, 0x46, 0x6D, 0xF1, 0xFC, 0xAA, 0xBA, 0x22, 0xCF, 0xCE, 0x57, 0x8D,
	  				0x67, 0x60, 0xE2, 0x45, 0x17, 0x4D, 0xD8, 0xD2, 0x97, 0xB7, 0x16, 0xED, 0x95, 0x11, 0x86, 0x53,
	  				0x46, 0x5C, 0xD3, 0x09, 0x3F, 0x87, 0xC3, 0xEE, 0x79, 0xF0, 0xDD, 0x4F, 0x8A, 0x5E, 0x4B, 0x4A,
	  				0x5E, 0xDA, 0xC2, 0x68, 0xDA, 0xDE, 0x1F, 0xAB, 0x7A, 0x7D, 0xB4, 0x1D, 0x94, 0xB3, 0xE8, 0xCB,
	  				0xB7, 0xA4, 0xD5, 0x66, 0xE7, 0x36, 0x6B, 0xC3, 0xFE, 0x87, 0x61, 0x17, 0xBF, 0xF2, 0xB1, 0xD5,
	  				0x2D, 0x9C, 0x31, 0x0A, 0x9C, 0x3D, 0xD7, 0x15, 0xE7, 0xEC, 0xB0, 0x7F, 0xFA, 0xCB, 0x55, 0x3E,
	  				0x10, 0x34, 0xB7, 0x10, 0x39, 0xDA, 0x6B, 0xA3, 0x8D, 0xE8, 0x6C, 0x94, 0xD2, 0x4D, 0x25, 0x30,
	  				0x93, 0x4B, 0x45, 0x56, 0xED, 0xA7, 0x80, 0x5B, 0x7F, 0xE4, 0x1C, 0xCD, 0xE4, 0x3C, 0x56, 0x7B,
	  				0xBF, 0xAF, 0xF5, 0x5C, 0x32, 0xD5, 0xB3, 0x1B, 0x5B, 0xD7, 0x11, 0xE5, 0x79, 0xCE, 0x96, 0x54,
	  				0x4C, 0xBA, 0x13, 0x0D, 0xA9, 0x09, 0x9B, 0x89, 0xAB, 0x82, 0x11, 0x89, 0x83, 0x7F, 0x35, 0x99,
	  				0x93, 0x2B, 0x87, 0x8B, 0x1D, 0x16, 0xA4, 0x35, 0x25, 0x1F, 0x15, 0xA7, 0x8F, 0xC1, 0xAF, 0x8B,
	  				0x3F, 0xC9, 0x98, 0x78, 0x9A, 0xB6, 0xF5, 0xC5, 0x79, 0x53, 0xEC, 0x91, 0xDA, 0x26, 0x21, 0x1B,
	  				0x19, 0x4C, 0x34, 0xC7, 0x47, 0x9C, 0x87, 0xF1, 0x58, 0xE3, 0x6F, 0xD5, 0x9F, 0xDB, 0xB2, 0x75,
	  				0xC2, 0x6A, 0xFE, 0xC6, 0xE1, 0x14, 0x6E, 0x83, 0xAA, 0x93, 0x6B, 0xF6, 0x37, 0x04, 0x23, 0x55,
	  				0x18, 0x5F, 0x2D, 0xCE, 0x27, 0xD6, 0xA2, 0x2C, 0x3C, 0xCE, 0xB5, 0x11, 0x08, 0x1C, 0x45, 0x25,
	  				0xAD, 0xBF, 0xAE, 0x48, 0x69, 0x89, 0xE7, 0x90, 0xE2, 0x11, 0xDC, 0x02, 0xD6, 0xA2, 0x2E, 0x47,
	  				0x27, 0x69, 0x4C, 0xDE, 0x94, 0xD1, 0x74, 0x9D, 0x79, 0x07, 0x52, 0x7A, 0xE1, 0x08, 0x8B, 0x38,
	  				0xD7, 0xE9, 0x0B, 0x2F, 0xCF, 0x9E, 0x4F, 0xC4, 0xDF, 0x65, 0x96, 0x4A, 0x8F, 0x56, 0xCE, 0x46,
	  				0xE5, 0xA5, 0x0B, 0xA2, 0x9F, 0x17, 0xDF, 0xC1, 0xBD, 0x7F, 0x51, 0x08, 0x93, 0xD2, 0x46, 0x6E,
	  				0x7F, 0xDB, 0x87, 0xF0, 0x76, 0x57, 0x5D, 0x68, 0xF8, 0xC6, 0xA6, 0xEA, 0x79, 0xBF, 0x1D, 0x3F,
	  				0x93, 0x3F, 0xCA, 0xD7, 0x75, 0xC5, 0xEB, 0x9D, 0xE4, 0x70, 0xA9, 0x62, 0x45, 0x7B, 0x5D, 0x7F,
	  				0xB8, 0x84, 0x58, 0x83, 0x06, 0x88, 0xB7, 0xD4, 0x3C, 0x7D, 0x1D, 0x17, 0xA2, 0x29, 0xEB, 0xA6,
	  				0x4F, 0xC5, 0xE1, 0x95, 0xAF, 0x8F, 0xDF, 0x52, 0x5C, 0x21, 0x15, 0xE5, 0x15, 0x3C, 0xF0, 0xF0,
	  				0x18, 0x2A, 0x19, 0x8C, 0x35, 0x44, 0x23, 0x2F, 0xAB, 0xE6, 0x24, 0xF4, 0xFD, 0x30, 0xC4, 0x3F,
	  				0xFF, 0xD9};

uint8_t config_vect[]={0x0A, 0x0A, 0x0A, 0xE0, 0x00, 0x10, 0x4A, 0x46, 0x49, 0x46, 0x00, 0x01, 0x01, 0x00, 0x00, 0x01,
	  				0x00, 0x01, 0x00, 0x00, 0xFF, 0xE2, 0x02, 0x28, 0x49, 0x43, 0x43, 0x5F, 0x50, 0x52};

uint8_t telemetry_vect[]={0x01, 0x01, 0x01, 0x02, 0x02, 0x10, 0x4A, 0x46, 0x49, 0x46, 0x00, 0x01, 0x01, 0x00, 0x00, 0x01,
			0x00, 0x01, 0x00, 0x00, 0xFF, 0xE2, 0x02, 0x28, 0x49, 0x43, 0x43, 0x5F, 0x50, 0x52};

TaskHandle_t FLASH_Handle;
TaskHandle_t OBC_Handle;
TaskHandle_t COMMS_Handle;
TaskHandle_t EPS_Handle;
TaskHandle_t PAYLOAD_Handle;
TaskHandle_t ADCS_Handle;
TaskHandle_t sTIM_Handle;

QueueHandle_t FLASH_Queue;

EventGroupHandle_t xEventGroup;

SemaphoreHandle_t xMutex;

/* USER CODE END PV */

void SystemClock_Config(void);
static void MX_GPIO_Init(void);
static void MX_I2C1_Init(void);
static void MX_RTC_Init(void);
static void MX_SPI2_Init(void);
static void MX_UART4_Init(void);
static void MX_TIM16_Init(void);
static void MX_ADC1_Init(void);
static void MX_DAC1_Init(void);
static void MX_TIM17_Init(void);
static void MX_TIM7_Init(void);
static void MX_TIM5_Init(void);

/* USER CODE BEGIN PFP */
void SystemClockConfig( void );
void Start_timer_16(void);
void Stop_timer_16(void);
void OBC_Task(void const * argument);
void COMMS_Task(void const * argument);
void ADCS_Task(void const * argument);
void PAYLOAD_Task(void const * argument);
void FLASH_Task(void const * argument);
void EPS_Task(void const * argument);
void sTIM_Task(void const * argument);
void Test_Task(void const * argument);

/* USER CODE END PFP */

int main(void)
{

  /* MCU Configuration--------------------------------------------------------*/

  /* Reset of all peripherals, Initializes the Flash interface and the Systick. */
  HAL_Init();

  /* Configure the system clock */
  SystemClock_Config();

  /* Initialize all configured peripherals */
  MX_GPIO_Init();
  MX_I2C1_Init();
  MX_RTC_Init();
  MX_SPI2_Init();
  MX_UART4_Init();
  MX_TIM16_Init();
  MX_ADC1_Init();
  MX_DAC1_Init();
  MX_TIM17_Init();
  MX_TIM7_Init();
  MX_TIM5_Init();
  /* USER CODE BEGIN 2 */
  xTaskCreate( FLASH_Task,     "FLASH",   FLASH_STACK_SIZE, NULL,   FLASH_PRIORITY, &FLASH_Handle  );
    //xTaskCreate( EPS_Task,         "EPS",     EPS_STACK_SIZE, NULL,   EPS_PRIORITY, &EPS_Handle  );
    //xTaskCreate( PAYLOAD_Task, "PAYLOAD", PAYLOAD_STACK_SIZE, NULL, PAYLOAD_PRIORITY, &PAYLOAD_Handle);
    //xTaskCreate( ADCS_Task,       "ADCS",    ADCS_STACK_SIZE, NULL,    ADCS_PRIORITY, &ADCS_Handle   );
    //xTaskCreate( OBC_Task,         "OBC",     OBC_STACK_SIZE, NULL,     OBC_PRIORITY, &OBC_Handle    );
    xTaskCreate( COMMS_Task,     "COMMS",   COMMS_STACK_SIZE, NULL,   COMMS_PRIORITY, &COMMS_Handle  );
    //xTaskCreate( sTIM_Task,     "sTIM",   sTIM_STACK_SIZE, NULL,   sTIM_PRIORITY, &sTIM_Handle  );
    //xTaskCreate( Test_Task,     "Test",   1000, NULL,   1, &Test_Handle  );

  FLASH_Queue = xQueueCreate(10,sizeof(QueueData_t)); // QUEUE : FIFO buffer for controlling the writing on the memory flash

  xEventGroup = xEventGroupCreate();                  // EVENT GROUP : communication object used for blocking events

  xMutex = xSemaphoreCreateMutex();

  vTaskStartScheduler();

  /* USER CODE END 2 */
}

void SystemClock_Config(void)
{
  RCC_OscInitTypeDef RCC_OscInitStruct = {0};
  RCC_ClkInitTypeDef RCC_ClkInitStruct = {0};

  /** Configure the main internal regulator output voltage
  */
  if (HAL_PWREx_ControlVoltageScaling(PWR_REGULATOR_VOLTAGE_SCALE1) != HAL_OK)
  {
    Error_Handler();
  }
  /** Initializes the RCC Oscillators according to the specified parameters
  * in the RCC_OscInitTypeDef structure.
  */
  RCC_OscInitStruct.OscillatorType = RCC_OSCILLATORTYPE_HSI|RCC_OSCILLATORTYPE_LSI;
  RCC_OscInitStruct.HSIState = RCC_HSI_ON;
  RCC_OscInitStruct.HSICalibrationValue = RCC_HSICALIBRATION_DEFAULT;
  RCC_OscInitStruct.LSIState = RCC_LSI_ON;
  RCC_OscInitStruct.PLL.PLLState = RCC_PLL_ON;
  RCC_OscInitStruct.PLL.PLLSource = RCC_PLLSOURCE_HSI;
  RCC_OscInitStruct.PLL.PLLM = 1;
  RCC_OscInitStruct.PLL.PLLN = 10;
  RCC_OscInitStruct.PLL.PLLP = RCC_PLLP_DIV7;
  RCC_OscInitStruct.PLL.PLLQ = RCC_PLLQ_DIV2;
  RCC_OscInitStruct.PLL.PLLR = RCC_PLLR_DIV2;
  if (HAL_RCC_OscConfig(&RCC_OscInitStruct) != HAL_OK)
  {
    Error_Handler();
  }
  /** Initializes the CPU, AHB and APB buses clocks
  */
  RCC_ClkInitStruct.ClockType = RCC_CLOCKTYPE_HCLK|RCC_CLOCKTYPE_SYSCLK
                              |RCC_CLOCKTYPE_PCLK1|RCC_CLOCKTYPE_PCLK2;
  RCC_ClkInitStruct.SYSCLKSource = RCC_SYSCLKSOURCE_PLLCLK;
  RCC_ClkInitStruct.AHBCLKDivider = RCC_SYSCLK_DIV1;
  RCC_ClkInitStruct.APB1CLKDivider = RCC_HCLK_DIV1;
  RCC_ClkInitStruct.APB2CLKDivider = RCC_HCLK_DIV1;

  if (HAL_RCC_ClockConfig(&RCC_ClkInitStruct, FLASH_LATENCY_4) != HAL_OK)
  {
    Error_Handler();
  }
}

static void MX_ADC1_Init(void)
{

  ADC_MultiModeTypeDef multimode = {0};
  ADC_ChannelConfTypeDef sConfig = {0};

  /** Common config
  */
  hadc1.Instance = ADC1;
  hadc1.Init.ClockPrescaler = ADC_CLOCK_ASYNC_DIV1;
  hadc1.Init.Resolution = ADC_RESOLUTION_12B;
  hadc1.Init.DataAlign = ADC_DATAALIGN_RIGHT;
  hadc1.Init.ScanConvMode = ADC_SCAN_DISABLE;
  hadc1.Init.EOCSelection = ADC_EOC_SINGLE_CONV;
  hadc1.Init.LowPowerAutoWait = DISABLE;
  hadc1.Init.ContinuousConvMode = DISABLE;
  hadc1.Init.NbrOfConversion = 1;
  hadc1.Init.DiscontinuousConvMode = DISABLE;
  hadc1.Init.ExternalTrigConv = ADC_SOFTWARE_START;
  hadc1.Init.ExternalTrigConvEdge = ADC_EXTERNALTRIGCONVEDGE_NONE;
  hadc1.Init.DMAContinuousRequests = DISABLE;
  hadc1.Init.Overrun = ADC_OVR_DATA_PRESERVED;
  hadc1.Init.OversamplingMode = DISABLE;
  if (HAL_ADC_Init(&hadc1) != HAL_OK)
  {
    Error_Handler();
  }
  /** Configure the ADC multi-mode
  */
  multimode.Mode = ADC_MODE_INDEPENDENT;
  if (HAL_ADCEx_MultiModeConfigChannel(&hadc1, &multimode) != HAL_OK)
  {
    Error_Handler();
  }
  /** Configure Regular Channel
  */
  sConfig.Channel = ADC_CHANNEL_5;
  sConfig.Rank = ADC_REGULAR_RANK_1;
  sConfig.SamplingTime = ADC_SAMPLETIME_2CYCLES_5;
  sConfig.SingleDiff = ADC_SINGLE_ENDED;
  sConfig.OffsetNumber = ADC_OFFSET_NONE;
  sConfig.Offset = 0;
  if (HAL_ADC_ConfigChannel(&hadc1, &sConfig) != HAL_OK)
  {
    Error_Handler();
  }

}

static void MX_DAC1_Init(void)
{

  DAC_ChannelConfTypeDef sConfig = {0};

  /** DAC Initialization
  */
  hdac1.Instance = DAC1;
  if (HAL_DAC_Init(&hdac1) != HAL_OK)
  {
    Error_Handler();
  }
  /** DAC channel OUT1 config
  */
  sConfig.DAC_SampleAndHold = DAC_SAMPLEANDHOLD_DISABLE;
  sConfig.DAC_Trigger = DAC_TRIGGER_NONE;
  sConfig.DAC_OutputBuffer = DAC_OUTPUTBUFFER_ENABLE;
  sConfig.DAC_ConnectOnChipPeripheral = DAC_CHIPCONNECT_DISABLE;
  sConfig.DAC_UserTrimming = DAC_TRIMMING_FACTORY;
  if (HAL_DAC_ConfigChannel(&hdac1, &sConfig, DAC_CHANNEL_1) != HAL_OK)
  {
    Error_Handler();
  }
  /** DAC channel OUT2 config
  */
  if (HAL_DAC_ConfigChannel(&hdac1, &sConfig, DAC_CHANNEL_2) != HAL_OK)
  {
    Error_Handler();
  }

}

static void MX_I2C1_Init(void)
{

  hi2c1.Instance = I2C1;
  hi2c1.Init.Timing = 0x10909CEC;
  hi2c1.Init.OwnAddress1 = 0;
  hi2c1.Init.AddressingMode = I2C_ADDRESSINGMODE_7BIT;
  hi2c1.Init.DualAddressMode = I2C_DUALADDRESS_DISABLE;
  hi2c1.Init.OwnAddress2 = 0;
  hi2c1.Init.OwnAddress2Masks = I2C_OA2_NOMASK;
  hi2c1.Init.GeneralCallMode = I2C_GENERALCALL_DISABLE;
  hi2c1.Init.NoStretchMode = I2C_NOSTRETCH_DISABLE;
  if (HAL_I2C_Init(&hi2c1) != HAL_OK)
  {
    Error_Handler();
  }
  /** Configure Analogue filter
  */
  if (HAL_I2CEx_ConfigAnalogFilter(&hi2c1, I2C_ANALOGFILTER_ENABLE) != HAL_OK)
  {
    Error_Handler();
  }
  /** Configure Digital filter
  */
  if (HAL_I2CEx_ConfigDigitalFilter(&hi2c1, 0) != HAL_OK)
  {
    Error_Handler();
  }

}

static void MX_RTC_Init(void)
{

  RTC_TimeTypeDef sTime = {0};
  RTC_DateTypeDef sDate = {0};

  /** Initialize RTC Only
  */
  hrtc.Instance = RTC;
  hrtc.Init.HourFormat = RTC_HOURFORMAT_24;
  hrtc.Init.AsynchPrediv = 127;
  hrtc.Init.SynchPrediv = 255;
  hrtc.Init.OutPut = RTC_OUTPUT_DISABLE;
  hrtc.Init.OutPutRemap = RTC_OUTPUT_REMAP_NONE;
  hrtc.Init.OutPutPolarity = RTC_OUTPUT_POLARITY_HIGH;
  hrtc.Init.OutPutType = RTC_OUTPUT_TYPE_OPENDRAIN;
  if (HAL_RTC_Init(&hrtc) != HAL_OK)
  {
    Error_Handler();
  }

  /** Initialize RTC and set the Time and Date
  */
  sTime.Hours = 0x0;
  sTime.Minutes = 0x0;
  sTime.Seconds = 0x0;
  sTime.DayLightSaving = RTC_DAYLIGHTSAVING_NONE;
  sTime.StoreOperation = RTC_STOREOPERATION_RESET;
  if (HAL_RTC_SetTime(&hrtc, &sTime, RTC_FORMAT_BCD) != HAL_OK)
  {
    Error_Handler();
  }
  sDate.WeekDay = RTC_WEEKDAY_MONDAY;
  sDate.Month = RTC_MONTH_JANUARY;
  sDate.Date = 0x1;
  sDate.Year = 0x0;

  if (HAL_RTC_SetDate(&hrtc, &sDate, RTC_FORMAT_BCD) != HAL_OK)
  {
    Error_Handler();
  }

}

static void MX_SPI2_Init(void)
{

  /* SPI2 parameter configuration*/
  hspi2.Instance = SPI2;
  hspi2.Init.Mode = SPI_MODE_MASTER;
  hspi2.Init.Direction = SPI_DIRECTION_2LINES;
  hspi2.Init.DataSize = SPI_DATASIZE_4BIT;
  hspi2.Init.CLKPolarity = SPI_POLARITY_LOW;
  hspi2.Init.CLKPhase = SPI_PHASE_1EDGE;
  hspi2.Init.NSS = SPI_NSS_HARD_OUTPUT;
  hspi2.Init.BaudRatePrescaler = SPI_BAUDRATEPRESCALER_2;
  hspi2.Init.FirstBit = SPI_FIRSTBIT_MSB;
  hspi2.Init.TIMode = SPI_TIMODE_DISABLE;
  hspi2.Init.CRCCalculation = SPI_CRCCALCULATION_DISABLE;
  hspi2.Init.CRCPolynomial = 7;
  hspi2.Init.CRCLength = SPI_CRC_LENGTH_DATASIZE;
  hspi2.Init.NSSPMode = SPI_NSS_PULSE_ENABLE;
  if (HAL_SPI_Init(&hspi2) != HAL_OK)
  {
    Error_Handler();
  }

}

static void MX_TIM5_Init(void)
{

  TIM_ClockConfigTypeDef sClockSourceConfig = {0};
  TIM_MasterConfigTypeDef sMasterConfig = {0};

  htim5.Instance = TIM5;
  htim5.Init.Prescaler = 0;
  htim5.Init.CounterMode = TIM_COUNTERMODE_DOWN;
  htim5.Init.Period = 8000-1;
  htim5.Init.ClockDivision = TIM_CLOCKDIVISION_DIV1;
  htim5.Init.AutoReloadPreload = TIM_AUTORELOAD_PRELOAD_ENABLE;
  if (HAL_TIM_Base_Init(&htim5) != HAL_OK)
  {
    Error_Handler();
  }
  sClockSourceConfig.ClockSource = TIM_CLOCKSOURCE_INTERNAL;
  if (HAL_TIM_ConfigClockSource(&htim5, &sClockSourceConfig) != HAL_OK)
  {
    Error_Handler();
  }
  sMasterConfig.MasterOutputTrigger = TIM_TRGO_RESET;
  sMasterConfig.MasterSlaveMode = TIM_MASTERSLAVEMODE_DISABLE;
  if (HAL_TIMEx_MasterConfigSynchronization(&htim5, &sMasterConfig) != HAL_OK)
  {
    Error_Handler();
  }

}

static void MX_TIM7_Init(void)
{

  TIM_MasterConfigTypeDef sMasterConfig = {0};

  htim7.Instance = TIM7;
  htim7.Init.Prescaler = 20000-1;
  htim7.Init.CounterMode = TIM_COUNTERMODE_UP;
  htim7.Init.Period = 1000-1;
  htim7.Init.AutoReloadPreload = TIM_AUTORELOAD_PRELOAD_DISABLE;
  if (HAL_TIM_Base_Init(&htim7) != HAL_OK)
  {
    Error_Handler();
  }
  sMasterConfig.MasterOutputTrigger = TIM_TRGO_RESET;
  sMasterConfig.MasterSlaveMode = TIM_MASTERSLAVEMODE_DISABLE;
  if (HAL_TIMEx_MasterConfigSynchronization(&htim7, &sMasterConfig) != HAL_OK)
  {
    Error_Handler();
  }

}

static void MX_TIM16_Init(void)
{

  htim16.Instance = TIM16;
  htim16.Init.Prescaler = 8000 - 1;
  htim16.Init.CounterMode = TIM_COUNTERMODE_UP;
  htim16.Init.Period = 10000 - 1;
  htim16.Init.ClockDivision = TIM_CLOCKDIVISION_DIV1;
  htim16.Init.RepetitionCounter = 0;
  htim16.Init.AutoReloadPreload = TIM_AUTORELOAD_PRELOAD_DISABLE;
  if (HAL_TIM_Base_Init(&htim16) != HAL_OK)
  {
    Error_Handler();
  }

}

static void MX_TIM17_Init(void)
{

  htim17.Instance = TIM17;
  htim17.Init.Prescaler = 48000-1;
  htim17.Init.CounterMode = TIM_COUNTERMODE_UP;
  htim17.Init.Period = 50000-1;
  htim17.Init.ClockDivision = TIM_CLOCKDIVISION_DIV1;
  htim17.Init.RepetitionCounter = 0;
  htim17.Init.AutoReloadPreload = TIM_AUTORELOAD_PRELOAD_DISABLE;
  if (HAL_TIM_Base_Init(&htim17) != HAL_OK)
  {
    Error_Handler();
  }

}

static void MX_UART4_Init(void)
{

  huart4.Instance = UART4;
  huart4.Init.BaudRate = 115200;
  huart4.Init.WordLength = UART_WORDLENGTH_8B;
  huart4.Init.StopBits = UART_STOPBITS_1;
  huart4.Init.Parity = UART_PARITY_NONE;
  huart4.Init.Mode = UART_MODE_TX_RX;
  huart4.Init.HwFlowCtl = UART_HWCONTROL_NONE;
  huart4.Init.OverSampling = UART_OVERSAMPLING_16;
  huart4.Init.OneBitSampling = UART_ONE_BIT_SAMPLE_DISABLE;
  huart4.AdvancedInit.AdvFeatureInit = UART_ADVFEATURE_NO_INIT;
  if (HAL_UART_Init(&huart4) != HAL_OK)
  {
    Error_Handler();
  }

}

static void MX_GPIO_Init(void)
{
  GPIO_InitTypeDef GPIO_InitStruct = {0};

  /* GPIO Ports Clock Enable */
  __HAL_RCC_GPIOC_CLK_ENABLE();
  __HAL_RCC_GPIOH_CLK_ENABLE();
  __HAL_RCC_GPIOA_CLK_ENABLE();
  __HAL_RCC_GPIOB_CLK_ENABLE();

  /*Configure GPIO pin Output Level */
  HAL_GPIO_WritePin(GPIOC, GPIO_PIN_0|GPIO_PIN_2|GPIO_PIN_3|GPIO_PIN_9, GPIO_PIN_RESET);

  /*Configure GPIO pin Output Level */
  HAL_GPIO_WritePin(GPIOA, GPIO_PIN_3|GPIO_PIN_9|GPIO_PIN_11|GPIO_PIN_12
                          |GPIO_PIN_15, GPIO_PIN_RESET);

  /*Configure GPIO pin Output Level */
  HAL_GPIO_WritePin(GPIOB, GPIO_PIN_0|GPIO_PIN_10|GPIO_PIN_11, GPIO_PIN_RESET);

  /*Configure GPIO pin : B1_Pin */
  GPIO_InitStruct.Pin = B1_Pin;
  GPIO_InitStruct.Mode = GPIO_MODE_IT_FALLING;
  GPIO_InitStruct.Pull = GPIO_NOPULL;
  HAL_GPIO_Init(B1_GPIO_Port, &GPIO_InitStruct);

  /*Configure GPIO pins : PC0 PC2 PC3 PC9 */
  GPIO_InitStruct.Pin = GPIO_PIN_0|GPIO_PIN_2|GPIO_PIN_3|GPIO_PIN_9;
  GPIO_InitStruct.Mode = GPIO_MODE_OUTPUT_PP;
  GPIO_InitStruct.Pull = GPIO_NOPULL;
  GPIO_InitStruct.Speed = GPIO_SPEED_FREQ_LOW;
  HAL_GPIO_Init(GPIOC, &GPIO_InitStruct);

  /*Configure GPIO pins : PA3 PA9 PA11 PA12
                           PA15 */
  GPIO_InitStruct.Pin = GPIO_PIN_3|GPIO_PIN_9|GPIO_PIN_11|GPIO_PIN_12
                          |GPIO_PIN_15;
  GPIO_InitStruct.Mode = GPIO_MODE_OUTPUT_PP;
  GPIO_InitStruct.Pull = GPIO_NOPULL;
  GPIO_InitStruct.Speed = GPIO_SPEED_FREQ_LOW;
  HAL_GPIO_Init(GPIOA, &GPIO_InitStruct);

  /*Configure GPIO pins : PA7 PA8 */
  GPIO_InitStruct.Pin = GPIO_PIN_7|GPIO_PIN_8;
  GPIO_InitStruct.Mode = GPIO_MODE_INPUT;
  GPIO_InitStruct.Pull = GPIO_NOPULL;
  HAL_GPIO_Init(GPIOA, &GPIO_InitStruct);

  /*Configure GPIO pin : PC4 */
  GPIO_InitStruct.Pin = GPIO_PIN_4;
  GPIO_InitStruct.Mode = GPIO_MODE_INPUT;
  GPIO_InitStruct.Pull = GPIO_NOPULL;
  HAL_GPIO_Init(GPIOC, &GPIO_InitStruct);

  /*Configure GPIO pins : PB0 PB10 PB11 */
  GPIO_InitStruct.Pin = GPIO_PIN_0|GPIO_PIN_10|GPIO_PIN_11;
  GPIO_InitStruct.Mode = GPIO_MODE_OUTPUT_PP;
  GPIO_InitStruct.Pull = GPIO_NOPULL;
  GPIO_InitStruct.Speed = GPIO_SPEED_FREQ_LOW;
  HAL_GPIO_Init(GPIOB, &GPIO_InitStruct);

  /*Configure GPIO pin : PA10 */
  GPIO_InitStruct.Pin = GPIO_PIN_10;
  GPIO_InitStruct.Mode = GPIO_MODE_IT_RISING;
  GPIO_InitStruct.Pull = GPIO_NOPULL;
  HAL_GPIO_Init(GPIOA, &GPIO_InitStruct);

  /*Configure GPIO pin : PB5 */
  GPIO_InitStruct.Pin = GPIO_PIN_5;
  GPIO_InitStruct.Mode = GPIO_MODE_INPUT;
  GPIO_InitStruct.Pull = GPIO_NOPULL;
  HAL_GPIO_Init(GPIOB, &GPIO_InitStruct);

  /* EXTI interrupt init*/
  HAL_NVIC_SetPriority(EXTI15_10_IRQn, 5, 0);
  HAL_NVIC_EnableIRQ(EXTI15_10_IRQn);

}

/* USER CODE BEGIN 4 */
void OBC_Task(void const * argument)
{
	uint8_t currentState;

	OBC_Init();

	 for(;;)
	 {
		 Read_Flash(CURRENT_STATE_ADDR,&currentState,1);

		 switch(currentState)
		 {
	  	  	  case _NOMINAL:
	  	  		  OBC_Nominal();
	  	  		  break;

	  	  	  case _CONTINGENCY:
	  	  		  OBC_Contingency();
	  	  		  break;

	  	  	  case _SUNSAFE:
	  	  		  OBC_Sunsafe();
	  	  		  break;

	  	  	  case _SURVIVAL:
	  	  		  OBC_Survival();
	  	  		  break;

	  	  	  default:
	  	  		  OBC_Survival();
	  	  		  break;
	  	  }
  }
}

void COMMS_Task(void const * argument)
{
	Send_to_WFQueue(&photo_vect,sizeof(photo_vect),PHOTO_ADDR,COMMSsender);
	//Send_to_WFQueue(&config_vect,sizeof(config_vect),PHOTO_ADDR,COMMSsender);
	//Send_to_WFQueue(&telemetry_vect,sizeof(telemetry_vect),PHOTO_ADDR,COMMSsender);

	for(;;)
	{
		COMMS_StateMachine();
	}
}

void ADCS_Task(void const * argument)
{
	uint32_t RX_ADCS_NOTIS;

	for(;;)
	{

		if (xTaskNotifyWait(0, 0xFFFFFFFF, &RX_ADCS_NOTIS, portMAX_DELAY) == pdPASS)
			{
				xTimerStart(xTimerAdcs,0);

				if((RX_ADCS_NOTIS & ADCS_TELEMETRY_NOTI) == ADCS_TELEMETRY_NOTI)
				{
					// Poll the Lateral Temperature Sensors
					// Store Lateral Temperature Sensors data on memory flash at TEMPLAT_ADDR

					// Poll the Gyroscope
					// Store Gyroscope data on memory flash at GYRO_ADDR

					// Poll the Photodiodes
					// Store Photodiodes data on memory flash at PHOTODIODES_ADDR

					// Poll the Magnetometers
					// Store Magnetometers data on memory flash at MAGNETOMETERS_ADDR

				}

				if((RX_ADCS_NOTIS & DETUMBLING_NOTI) == DETUMBLING_NOTI)
				{
					// Check Gyroscope--> Rotating?
							// If Rotating --> Bdot algotithm for Detumbling
				}

				if((RX_ADCS_NOTIS & CHECKROTATE_NOTI) == CHECKROTATE_NOTI) // Change CHECK_ROTATE_NOTI
				{
					// Compute temperature gradient between PQ faces
							// If Excessive Temperature Gradient --> ROTATE
				}

				if((RX_ADCS_NOTIS & POINTING_NOTI) == POINTING_NOTI)
				{
					// Nadir Pointing Algorithm
					xEventGroupSetBits(xEventGroup, PAYLOAD_POINTINGDONE_EVENT);
				}

				if((RX_ADCS_NOTIS & STOP_POINTING_NOTI) == STOP_POINTING_NOTI)
				{
					// Stop Nadir Pointing Algorithm
				}

				if((RX_ADCS_NOTIS & SUNSAFE_NOTI) == SUNSAFE_NOTI)
				{
					// Rotate directly
				}

				xTimerStop(xTimerAdcs,0);
			}
	}
}

void PAYLOAD_Task(void const * argument)
{
	uint32_t RX_PAYLOAD_NOTIS, phototime, time, dT;
	EventBits_t EventBits;

	for(;;)
	{

		if (xTaskNotifyWait(0, 0xFFFFFFFF, &RX_PAYLOAD_NOTIS, portMAX_DELAY) == pdPASS)
			{

				if((RX_PAYLOAD_NOTIS & ACTIVATE_PAYLOAD)==ACTIVATE_PAYLOAD)
				{
					xTimerStart(xTimerPayload,0);
					// Set Camara Resolution
					// Set Camara Compressibility

					PAYLOAD_RTC_SetTime(&hrtc); // Synchronize PQ time with GS time

					Read_Flash(PHOTOTIME_ADDR, &phototime, 4);

					PAYLOAD_RTC_GetTime(&hrtc); // Get current time

					Read_Flash(RTC_TIME_ADDR, &time, 4);

					dT = phototime - time; // Period until photo time

					xTimerChangePeriod(xTimerPhoto,pdMS_TO_TICKS(dT*1000),0);
					xTimerStart(xTimerPhoto,0);

					xTimerStop(xTimerPayload,0);

					EventBits = xEventGroupWaitBits(xEventGroup, PAYLOAD_TIMEFORPHOTO_EVENT | PAYLOAD_POINTINGDONE_EVENT, 0, true, portMAX_DELAY);

					xTimerStart(xTimerPayload,0);

					if( ((EventBits & PAYLOAD_TIMEFORPHOTO_EVENT) == PAYLOAD_TIMEFORPHOTO_EVENT) && ((EventBits & PAYLOAD_POINTINGDONE_EVENT) == PAYLOAD_POINTINGDONE_EVENT) )
					{
						// Take Photo

						xEventGroupClearBits(xEventGroup, PAYLOAD_TIMEFORPHOTO_EVENT | PAYLOAD_POINTINGDONE_EVENT);
					}

					xTimerStop(xTimerPayload,0);
				}
			}
	}
}

void FLASH_Task(void const * argument) // GateKeeper Task of Writing on Flash Memory
{
	QueueData_t RxQueueData;
	BaseType_t xQueueStatus;
	UBaseType_t numMessageWaiting;
	int i;

	for(;;)
	{
		xQueueStatus = xQueuePeek(FLASH_Queue,&RxQueueData,portMAX_DELAY); // This "attempt to read" moves the task from Running state to the Blocked State!
																		   // This is important as this task will be the one with highest priority.
																		   // portMAX_DELAY--> specifies that the task will wait indefinitely in blocked state

		numMessageWaiting = uxQueueMessagesWaiting(FLASH_Queue);

		for(i=0;i<numMessageWaiting;i++) // Write on Flash all messages from the Queue
		{
			xQueueStatus = xQueueReceive(FLASH_Queue,&RxQueueData,100);

			if(xQueueStatus==pdPASS)
			{
				Write_Flash(RxQueueData.addr,RxQueueData.pointer,RxQueueData.arrayLength);
			}
		}

		xQueueReset(FLASH_Queue); // Reset a queue back to its original empty state (it should be already empty)
	}
}

void EPS_Task(void const * argument)
{
	uint32_t RX_EPS_NOTIS;

	for(;;)
	{
		if (xTaskNotifyWait(0, 0xFFFFFFFF, &RX_EPS_NOTIS, portMAX_DELAY)==pdPASS)
		{
			if((RX_EPS_NOTIS & EPS_BATTERY_NOTI) == EPS_BATTERY_NOTI)
			{
				uint8_t state, prev_state, batt, nom, low, crit;

				// Read Battery Capacity

				batt = 95; // arbitrary value by now

				Read_Flash(CURRENT_STATE_ADDR, &state, 1);
				Read_Flash(PREVIOUS_STATE_ADDR, &prev_state, 1);
				Read_Flash(NOMINAL_ADDR, &nom, 1);
				Read_Flash(LOW_ADDR, &low, 1);
				Read_Flash(CRITICAL_ADDR, &crit, 1);

				Send_to_WFQueue(&state, 1, PREVIOUS_STATE_ADDR, EPSsender); // store the current state as previous

				switch(state)
				{
					case _INIT :
					{
						if(batt>=nom){state = _NOMINAL;}
						else{state = _CONTINGENCY;}
					}

					case _NOMINAL :
						{
							if(batt>=nom){state = _NOMINAL;}
							else{state = _CONTINGENCY;}
						}

					case _CONTINGENCY :
						{
							if(batt>=nom){state = _NOMINAL;}
							else if(batt<low){state = _SUNSAFE;}
							else{state = _CONTINGENCY;}
						}
					case _SUNSAFE :
						{
							if(batt>=low){state = _CONTINGENCY;}
							else if(batt<crit){state = _SURVIVAL;}
							else{state = _SUNSAFE;}
						}
					case _SURVIVAL :
						{
							if(batt>=crit){state = _SUNSAFE;} // Through telecommands (SURVIVAL-->SUNSAFE)
																		// Hear after sleep
							else{state = _SURVIVAL;}
						}
					default:{state = prev_state;}
				}

				Send_to_WFQueue(&state, 1, CURRENT_STATE_ADDR, EPSsender);
			}

			if((RX_EPS_NOTIS & EPS_HEATER_NOTI) == EPS_HEATER_NOTI)
			{
				// If we are charging the battery
					// Read the battery temperature sensor
						// If (temp<threshold && Heater OFF) --> Heater ON
						// Else IF (temp>threshold && Heater ON) --> Heater OFF
			}

			if((RX_EPS_NOTIS & EPS_TELEMETRY_NOTI) == EPS_TELEMETRY_NOTI)
			{
				// Read battery temperature sensor
				// Store battery temperature sensor on memory flash at BATT_TEMP_ADDR

				// Read battery capacity
				// Store battery capacity on memory flash at BATT_CAP_ADDR

			}
		}
	}
}

void sTIM_Task(void const * argument)
{
	uint32_t sTIM_RX_NOTIS;

	uint8_t vCount[5]={0,0,0,0,0}; // {OBC, COMMS, ADCS, PAYLOAD, EPS}
			// vCount[i]==0 && Timer Inactive --> Unused task
			// vCount[i]==0 && Timer Active --> Active period
			// vCount[i]==1 && Timer Active --> Suspended period
			// vCount[i]==1 && Timer Inactive --> Impossible state XXXX

	uint8_t vHalfwayTask[5]={0,0,0,0,0};
	TaskHandle_t vTask[5]={OBC_Handle,COMMS_Handle,ADCS_Handle,PAYLOAD_Handle, EPS_Handle};
	TimerHandle_t vTimer[5]={xTimerObc,xTimerComms,xTimerAdcs,xTimerPayload,xTimerEps};
	uint32_t vActivePeriod[5]={OBC_ACTIVE_PERIOD, COMMS_ACTIVE_PERIOD, ADCS_ACTIVE_PERIOD, PAYLOAD_ACTIVE_PERIOD, EPS_ACTIVE_PERIOD};
	uint32_t vSusPeriod[5]={OBC_SUSPENDED_PERIOD, COMMS_SUSPENDED_PERIOD, ADCS_SUSPENDED_PERIOD, PAYLOAD_SUSPENDED_PERIOD, EPS_SUSPENDED_PERIOD};

	uint8_t sender, i;

	for(;;)
	{
		if(xTaskNotifyWait(0, 0xFFFF, &sTIM_RX_NOTIS, portMAX_DELAY)==pdPASS)
			{
				if((sTIM_RX_NOTIS & sTIM_OBC_NOTI) == sTIM_OBC_NOTI){sender = OBC;}
				if((sTIM_RX_NOTIS & sTIM_COMMS_NOTI) == sTIM_COMMS_NOTI){sender = COMMS;}
				if((sTIM_RX_NOTIS & sTIM_ADCS_NOTI) == sTIM_ADCS_NOTI){sender = ADCS;}
				if((sTIM_RX_NOTIS & sTIM_PAYLOAD_NOTI) == sTIM_PAYLOAD_NOTI){sender = PAYLOAD;}
				if((sTIM_RX_NOTIS & sTIM_EPS_NOTI) == sTIM_EPS_NOTI){sender = EPS;}
			}

		if(vCount[sender]=0) // Exceeded active period
		{
			vCount[sender]++;
			xTimerChangePeriod(vTimer[sender],vSusPeriod[sender],0);
			xTimerReset(vTimer[sender],0);
			xTimerStart(vTimer[sender],0);
			vTaskSuspend(vTask[sender]);
		}

		else // Finished suspended period
		{
			vCount[sender]--;
			for(i=0;i<(sizeof(vCount)/sizeof(uint8_t));i++)
			{
				if((xTimerIsTimerActive(vTimer[i])==pdTRUE)
						&&(vCount[i]==0)
						&&(uxTaskPriorityGet(vTask[sender])>uxTaskPriorityGet(vTask[i])) )
				{
					xTimerStop(vTimer[i],0);

					xTimerChangePeriod(vTimer[sender],vActivePeriod[sender],0);
					xTimerReset(vTimer[sender],0);
					xTimerStart(vTimer[sender],0);

					vTaskResume(vTask[sender]);
				}
			}
		}
	}
}

void Test_Task(void const * argument)
{
	for(;;)
	{

		uint32_t size = sizeof(photo_vect);

		uint32_t settime = 1680786088; //1680786169 // Year 2023; Month 4; Day 6; Hour 15; Minutes 1; Seconds 28
		Send_to_WFQueue(&settime, 4, SET_TIME_ADDR, OBCsender);
		PAYLOAD_RTC_SetTime(&hrtc);
		PAYLOAD_RTC_GetTime(&hrtc);
	}
}

void Init_Peripherals()
{
	MX_GPIO_Init();
	MX_I2C1_Init();
	MX_RTC_Init();
	MX_SPI2_Init();
	MX_UART4_Init();
	MX_TIM16_Init();
	MX_ADC1_Init();
	MX_DAC1_Init();
	MX_TIM17_Init();
	MX_TIM7_Init();
	MX_TIM5_Init();
}

void SystemClockConfig( void )
{

  RCC_OscInitTypeDef RCC_OscInitStruct;
  RCC_ClkInitTypeDef RCC_ClkInitStruct;
  RCC_PeriphCLKInitTypeDef PeriphClkInit;

  __HAL_RCC_LSEDRIVE_CONFIG(RCC_LSEDRIVE_LOW);

  RCC_OscInitStruct.OscillatorType = RCC_OSCILLATORTYPE_HSI|RCC_OSCILLATORTYPE_LSE;
  RCC_OscInitStruct.LSEState = RCC_LSE_ON;
  RCC_OscInitStruct.HSIState = RCC_HSI_ON;
  RCC_OscInitStruct.HSICalibrationValue = 16;
  RCC_OscInitStruct.PLL.PLLState = RCC_PLL_ON;
  RCC_OscInitStruct.PLL.PLLSource = RCC_PLLSOURCE_HSI;
  RCC_OscInitStruct.PLL.PLLM = 1;
  RCC_OscInitStruct.PLL.PLLN = 10;
  RCC_OscInitStruct.PLL.PLLP = RCC_PLLP_DIV7;
  RCC_OscInitStruct.PLL.PLLQ = RCC_PLLQ_DIV2;
  RCC_OscInitStruct.PLL.PLLR = RCC_PLLR_DIV2;
  if (HAL_RCC_OscConfig(&RCC_OscInitStruct) != HAL_OK)
  {
    //assert_failed(__FILE__, __LINE__);
	  assert_param( FAIL );

  }

  RCC_ClkInitStruct.ClockType = RCC_CLOCKTYPE_HCLK|RCC_CLOCKTYPE_SYSCLK
                              |RCC_CLOCKTYPE_PCLK1|RCC_CLOCKTYPE_PCLK2;
  RCC_ClkInitStruct.SYSCLKSource = RCC_SYSCLKSOURCE_PLLCLK;
  RCC_ClkInitStruct.AHBCLKDivider = RCC_SYSCLK_DIV1;
  RCC_ClkInitStruct.APB1CLKDivider = RCC_HCLK_DIV1;
  RCC_ClkInitStruct.APB2CLKDivider = RCC_HCLK_DIV1;

  if (HAL_RCC_ClockConfig(&RCC_ClkInitStruct, FLASH_LATENCY_4) != HAL_OK)
  {
    //assert_failed(__FILE__, __LINE__);
	  assert_param( FAIL );
  }

  PeriphClkInit.PeriphClockSelection = RCC_PERIPHCLK_RTC|RCC_PERIPHCLK_USART2;
  PeriphClkInit.Usart2ClockSelection = RCC_USART2CLKSOURCE_PCLK1;
  PeriphClkInit.RTCClockSelection = RCC_RTCCLKSOURCE_LSE;
  if (HAL_RCCEx_PeriphCLKConfig(&PeriphClkInit) != HAL_OK)
  {
    //assert_failed(__FILE__, __LINE__);
	  assert_param( FAIL );
  }

  if (HAL_PWREx_ControlVoltageScaling(PWR_REGULATOR_VOLTAGE_SCALE1) != HAL_OK)
  {
    //assert_failed(__FILE__, __LINE__);
	  assert_param( FAIL );
  }
    //HAL_SYSTICK_Config(HAL_RCC_GetHCLKFreq()/1000);
    //HAL_SYSTICK_CLKSourceConfig(SYSTICK_CLKSOURCE_HCLK);
    //HAL_NVIC_SetPriority(SysTick_IRQn, 0, 0);

  HAL_NVIC_SetPriority(SPI2_IRQn, 0, 0);
  HAL_NVIC_EnableIRQ(SPI2_IRQn);
}

void eighttosixfour (void){

	uint64_t dataVect[sizeof(photo_vect)/8+1];
	memcpy(&dataVect, photo_vect, sizeof(dataVect));
	uint64_t info_write;
	info_write=dataVect;
	//Write_Flash(TEST_ADDRESS3, &info_write, (sizeof(photo_vect)/8+1));
}

// Callback: timer has reset
void HAL_TIM_PeriodElapsedCallback(TIM_HandleTypeDef *htim){

	if (htim == &htim17){
		if (beacon_counter >= 1){	// We TX beacon once every minute
			tx_beacon();
			beacon_counter = 0;
			HAL_TIM_Base_Stop_IT(&htim17);
		} else{
			beacon_counter = beacon_counter + 1;
		}
	}
	else if (htim == &htim16){
		if (start_timer){
			start_timer = false;
		} else if (stop_timer){
			stop_timer = false;
		} else{
			comms_timmer();
			//timeout_counter = 0;
		}
	}

	else if (htim == &htim7){

	}
}

void Stop_timer_16(void){
	stop_timer = true;
	HAL_TIM_Base_Stop_IT(&htim16);
	//manualDelayMS(1);
}

void Start_timer_16(void){
	start_timer = true;
	HAL_TIM_Base_Start_IT(&htim16);
	//manualDelayMS(1);
}
/* USER CODE END 4 */

void Error_Handler(void)
{
  __disable_irq();
  while (1)
  {
  }
}

/************************ (C) COPYRIGHT STMicroelectronics *****END OF FILE****/

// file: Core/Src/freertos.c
/* USER CODE BEGIN Header */
/**
  ******************************************************************************
  * File Name          : freertos.c
  * Description        : Code for freertos applications
  ******************************************************************************
  * @attention
  *
  * <h2><center>&copy; Copyright (c) 2023 STMicroelectronics.
  * All rights reserved.</center></h2>
  *
  * This software component is licensed by ST under Ultimate Liberty license
  * SLA0044, the "License"; You may not use this file except in compliance with
  * the License. You may obtain a copy of the License at:
  *                             www.st.com/SLA0044
  *
  ******************************************************************************
  */
/* USER CODE END Header */

#include "FreeRTOS.h"
#include "task.h"
#include "main.h"

/* GetIdleTaskMemory prototype (linked to static allocation support) */
void vApplicationGetIdleTaskMemory( StaticTask_t **ppxIdleTaskTCBBuffer, StackType_t **ppxIdleTaskStackBuffer, uint32_t *pulIdleTaskStackSize );

/* GetTimerTaskMemory prototype (linked to static allocation support) */
void vApplicationGetTimerTaskMemory( StaticTask_t **ppxTimerTaskTCBBuffer, StackType_t **ppxTimerTaskStackBuffer, uint32_t *pulTimerTaskStackSize );

/* USER CODE BEGIN GET_IDLE_TASK_MEMORY */
static StaticTask_t xIdleTaskTCBBuffer;
static StackType_t xIdleStack[configMINIMAL_STACK_SIZE];

void vApplicationGetIdleTaskMemory( StaticTask_t **ppxIdleTaskTCBBuffer, StackType_t **ppxIdleTaskStackBuffer, uint32_t *pulIdleTaskStackSize )
{
  *ppxIdleTaskTCBBuffer = &xIdleTaskTCBBuffer;
  *ppxIdleTaskStackBuffer = &xIdleStack[0];
  *pulIdleTaskStackSize = configMINIMAL_STACK_SIZE;
  /* place for user code */
}
/* USER CODE END GET_IDLE_TASK_MEMORY */

/* USER CODE BEGIN GET_TIMER_TASK_MEMORY */
static StaticTask_t xTimerTaskTCBBuffer;
static StackType_t xTimerStack[configTIMER_TASK_STACK_DEPTH];

void vApplicationGetTimerTaskMemory( StaticTask_t **ppxTimerTaskTCBBuffer, StackType_t **ppxTimerTaskStackBuffer, uint32_t *pulTimerTaskStackSize )
{
  *ppxTimerTaskTCBBuffer = &xTimerTaskTCBBuffer;
  *ppxTimerTaskStackBuffer = &xTimerStack[0];
  *pulTimerTaskStackSize = configTIMER_TASK_STACK_DEPTH;
  /* place for user code */
}
/* USER CODE END GET_TIMER_TASK_MEMORY */

/************************ (C) COPYRIGHT STMicroelectronics *****END OF FILE****/
